# SAM3U1E register map
File version: 0
Registers are 32-bit, read-write, reset 0x0 unless marked. A register's access mark holds for its fields unless they carry their own. Offsets are from the block's base; [hi:lo] are bit positions; {n}, {i} and the like mark numbered series.

## ADC12B — Analog-to-Digital-Converter 12bits
Base 0x400A8000; register names take the prefix ADC12B_
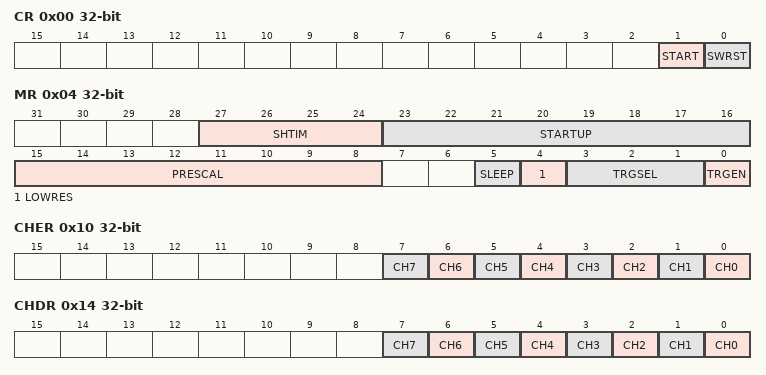
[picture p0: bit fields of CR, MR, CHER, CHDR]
0x00 CR wo reset not defined — Control Register
  [1] START — Start Conversion
  [0] SWRST — Software Reset
0x04 MR — Mode Register
  [27:24] SHTIM — Sample & Hold Time
  [23:16] STARTUP — Start Up Time
  [15:8] PRESCAL — Prescaler Rate Selection
  [5] SLEEP — Sleep Mode
  [4] LOWRES — Resolution
  [3:1] TRGSEL — Trigger Selection
  [0] TRGEN — Trigger Enable
0x10 CHER wo reset not defined — Channel Enable Register
  [n] CH{n} (n=0..7) — Channel {n} Enable
0x14 CHDR wo reset not defined — Channel Disable Register
  [n] CH{n} (n=0..7)
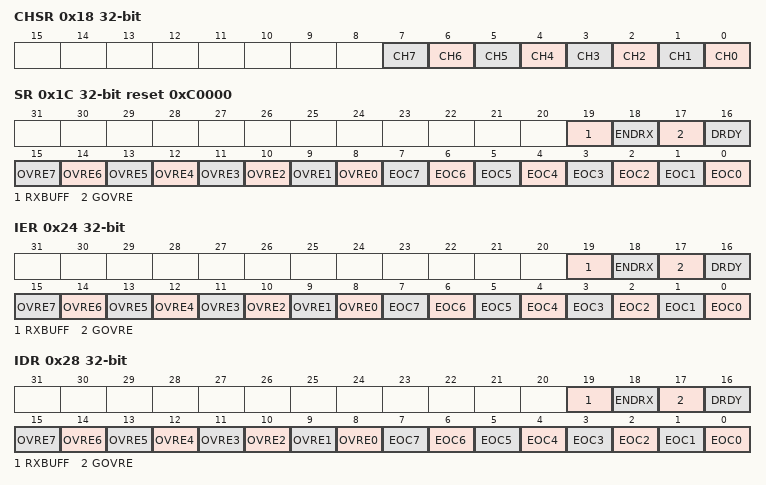
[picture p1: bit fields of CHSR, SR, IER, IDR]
0x18 CHSR ro — Channel Status Register
  [n] CH{n} (n=0..7) — Channel {n} Status
0x1C SR ro reset 0xC0000 — Status Register
  [19] RXBUFF — RX Buffer Full
  [18] ENDRX — End of RX Buffer
  [17] GOVRE — General Overrun Error
  [16] DRDY — Data Ready
  [n+8] OVRE{n} (n=0..7) — Overrun Error {n}
  [n] EOC{n} (n=0..7) — End of Conversion {n}
0x20 LCDR ro — Last Converted Data Register
  [11:0] LDATA — Last Data Converted
0x24 IER wo reset not defined — Interrupt Enable Register
  [19] RXBUFF — Receive Buffer Full Interrupt Enable
  [18] ENDRX — End of Receive Buffer Interrupt Enable
  [17] GOVRE — General Overrun Error Interrupt Enable
  [16] DRDY — Data Ready Interrupt Enable
  [n+8] OVRE{n} (n=0..7) — Overrun Error Interrupt Enable {n}
  [n] EOC{n} (n=0..7) — End of Conversion Interrupt Enable {n}
0x28 IDR wo reset not defined — Interrupt Disable Register
  [19] RXBUFF — Receive Buffer Full Interrupt Disable
  [18] ENDRX — End of Receive Buffer Interrupt Disable
  [17] GOVRE — General Overrun Error Interrupt Disable
  [16] DRDY — Data Ready Interrupt Disable
  [n+8] OVRE{n} (n=0..7) — Overrun Error Interrupt Disable {n}
  [n] EOC{n} (n=0..7) — End of Conversion Interrupt Disable {n}
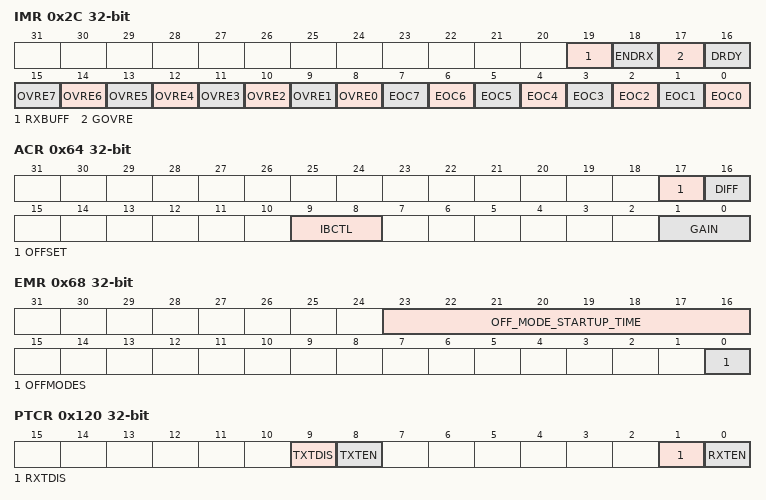
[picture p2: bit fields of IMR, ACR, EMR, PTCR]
0x2C IMR ro — Interrupt Mask Register
  [19] RXBUFF — Receive Buffer Full Interrupt Mask
  [18] ENDRX — End of Receive Buffer Interrupt Mask
  [17] GOVRE — General Overrun Error Interrupt Mask
  [16] DRDY — Data Ready Interrupt Mask
  [n+8] OVRE{n} (n=0..7) — Overrun Error Interrupt Mask {n}
  [n] EOC{n} (n=0..7) — End of Conversion Interrupt Mask {n}
{0x30+4i} CDR{i} (i=0..7) ro reset not defined — Channel Data Register
  [11:0] DATA — Converted Data
0x64 ACR — Analog Control Register
  [17] OFFSET — Input OFFSET
  [16] DIFF — Differential Mode
  [9:8] IBCTL — Bias Current Control
  [1:0] GAIN — Input Gain
0x68 EMR — Extended Mode Register
  [23:16] OFF_MODE_STARTUP_TIME — Startup Time
  [0] OFFMODES — Off Mode if Sleep Bit (ADC12B_MR) = 1
0x100 RPR — Receive Pointer Register
  [31:0] RXPTR
0x104 RCR — Receive Counter Register
  [15:0] RXCTR
0x108 TPR — Transmit Pointer Register
  [31:0] TXPTR — Transmit Counter Register
0x10C TCR — Transmit Counter Register
  [15:0] TXCTR
0x110 RNPR — Receive Next Pointer Register
  [31:0] RXNPTR — Receive Next Pointer
0x114 RNCR — Receive Next Counter Register
  [15:0] RXNCTR — Receive Next Counter
0x118 TNPR — Transmit Next Pointer Register
  [31:0] TXNPTR — Transmit Next Pointer
0x11C TNCR — Transmit Next Counter Register
  [15:0] TXNCTR — Transmit Counter Next
0x120 PTCR wo — Transfer Control Register
  [9] TXTDIS — Transmitter Transfer Disable
  [8] TXTEN — Transmitter Transfer Enable
  [1] RXTDIS — Receiver Transfer Disable
  [0] RXTEN — Receiver Transfer Enable
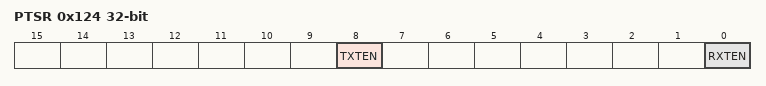
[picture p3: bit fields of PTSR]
0x124 PTSR ro — Transfer Status Register
  [8] TXTEN — Transmitter Transfer Enable
  [0] RXTEN — Receiver Transfer Enable

## ADC — Analog-to-digital Converter
Base 0x400AC000; register names take the prefix ADC_
Registers as ADC12B, without ACR, EMR; these are added or differ:
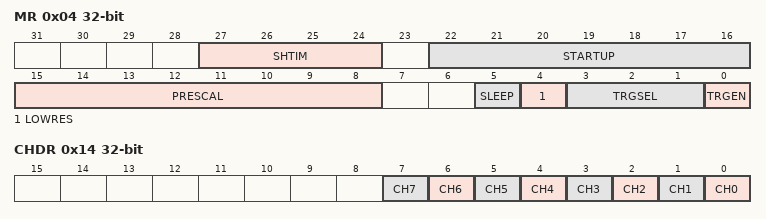
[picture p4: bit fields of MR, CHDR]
0x04 MR — Mode Register
  [27:24] SHTIM — Sample & Hold Time
  [22:16] STARTUP — Start Up Time
  [15:8] PRESCAL — Prescaler Rate Selection
  [5] SLEEP — Sleep Mode
  [4] LOWRES — Resolution
  [3:1] TRGSEL — Trigger Selection
  [0] TRGEN — Trigger Enable
0x14 CHDR wo reset not defined — Channel Disable Register
  [n] CH{n} (n=0..7) — Channel {n} Disable
0x20 LCDR ro — Last Converted Data Register
  [9:0] LDATA — Last Data Converted
{0x30+4i} CDR{i} (i=0..7) ro reset not defined — Channel Data Register
  [9:0] DATA — Converted Data

## Notices in the file
Copyright (c) 2011, Atmel Corporation
All rights reserved.
Redistribution and use in source and binary forms, with or without
modification, are permitted provided that the following condition is met:
- Redistributions of source code must retain the above copyright notice,
this list of conditions and the disclaimer below.
Atmel's name may not be used to endorse or promote products derived from
this software without specific prior written permission.
DISCLAIMER:  THIS SOFTWARE IS PROVIDED BY ATMEL "AS IS" AND ANY EXPRESS OR
IMPLIED WARRANTIES, INCLUDING, BUT NOT LIMITED TO, THE IMPLIED WARRANTIES OF
MERCHANTABILITY, FITNESS FOR A PARTICULAR PURPOSE AND NON-INFRINGEMENT ARE
DISCLAIMED. IN NO EVENT SHALL ATMEL BE LIABLE FOR ANY DIRECT, INDIRECT,
INCIDENTAL, SPECIAL, EXEMPLARY, OR CONSEQUENTIAL DAMAGES (INCLUDING, BUT NOT
LIMITED TO, PROCUREMENT OF SUBSTITUTE GOODS OR SERVICES; LOSS OF USE, DATA,
OR PROFITS; OR BUSINESS INTERRUPTION) HOWEVER CAUSED AND ON ANY THEORY OF
LIABILITY, WHETHER IN CONTRACT, STRICT LIABILITY, OR TORT (INCLUDING
NEGLIGENCE OR OTHERWISE) ARISING IN ANY WAY OUT OF THE USE OF THIS SOFTWARE,
EVEN IF ADVISED OF THE POSSIBILITY OF SUCH DAMAGE.
